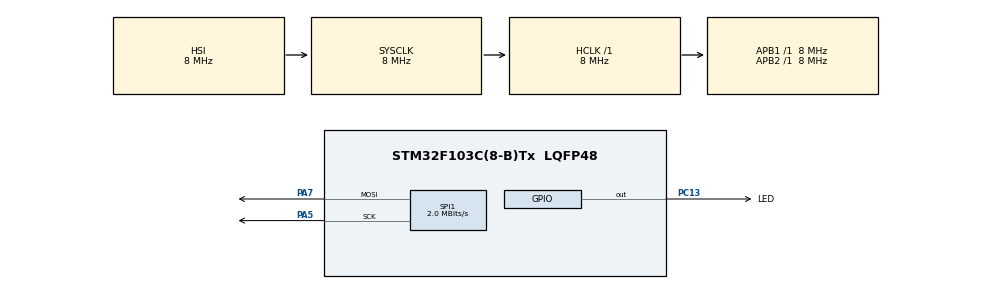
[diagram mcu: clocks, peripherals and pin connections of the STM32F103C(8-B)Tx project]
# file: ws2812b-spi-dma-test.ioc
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Mcu.Family=STM32F1
Dma.SPI1_TX.0.MemInc=DMA_MINC_ENABLE
Dma.SPI1_TX.0.PeriphInc=DMA_PINC_DISABLE
PA7.Mode=TX_Only_Simplex_Unidirect_Master
SPI1.VirtualType=VM_MASTER
PC13-TAMPER-RTC.Signal=GPIO_Output
SPI1.CLKPhase=SPI_PHASE_2EDGE
ProjectManager.StackSize=0x400
NVIC.DMA1_Channel3_IRQn=true\:0\:0\:false\:false\:true\:false\:true
PA13.Signal=SYS_JTMS-SWDIO
ProjectManager.TargetToolchain=Makefile
SPI1.Direction=SPI_DIRECTION_2LINES
Dma.SPI1_TX.0.PeriphDataAlignment=DMA_PDATAALIGN_BYTE
RCC.HCLKFreq_Value=8000000
Dma.SPI1_TX.0.Direction=DMA_MEMORY_TO_PERIPH
RCC.APB2TimFreq_Value=8000000
SPI1.CalculateBaudRate=2.0 MBits/s
RCC.USBFreq_Value=8000000
RCC.AHBFreq_Value=8000000
PA5.Signal=SPI1_SCK
board=custom
PC13-TAMPER-RTC.GPIO_Label=LED
RCC.APB2Freq_Value=8000000
SPI1.Mode=SPI_MODE_MASTER
PA14.Mode=Serial_Wire
Dma.SPI1_TX.0.Instance=DMA1_Channel3
PA13.Mode=Serial_Wire
Mcu.Name=STM32F103C(8-B)Tx
Dma.SPI1_TX.0.Mode=DMA_NORMAL
RCC.SYSCLKFreq_VALUE=8000000
Mcu.Package=LQFP48
PA14.Signal=SYS_JTCK-SWCLK
ProjectManager.HeapSize=0x200
Dma.SPI1_TX.0.Priority=DMA_PRIORITY_LOW
Dma.SPI1_TX.0.MemDataAlignment=DMA_MDATAALIGN_BYTE
NVIC.PriorityGroup=NVIC_PRIORITYGROUP_4
RCC.APB1TimFreq_Value=8000000
Dma.Request0=SPI1_TX
RCC.APB1Freq_Value=8000000
SPI1.BaudRatePrescaler=SPI_BAUDRATEPRESCALER_4
PA5.Mode=TX_Only_Simplex_Unidirect_Master
PA7.Signal=SPI1_MOSI

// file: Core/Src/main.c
/* USER CODE BEGIN Header */
/**
  ******************************************************************************
  * @file           : main.c
  * @brief          : Main program body
  ******************************************************************************
  * @attention
  *
  * <h2><center>&copy; Copyright (c) 2021 STMicroelectronics.
  * All rights reserved.</center></h2>
  *
  * This software component is licensed by ST under BSD 3-Clause license,
  * the "License"; You may not use this file except in compliance with the
  * License. You may obtain a copy of the License at:
  *                        opensource.org/licenses/BSD-3-Clause
  *
  ******************************************************************************
  */
/* USER CODE END Header */
#include "main.h"

/* USER CODE BEGIN Includes */
#include <string.h>
#include <stdlib.h>
#include <math.h>
#include <alloca.h>
/* USER CODE END Includes */

/* USER CODE BEGIN PD */
#define SPI_BITS_PER_BIT 3
#define NUM_RESET_BYTES 100
/* USER CODE END PD */

SPI_HandleTypeDef hspi1;
DMA_HandleTypeDef hdma_spi1_tx;

void SystemClock_Config(void);
static void MX_GPIO_Init(void);
static void MX_DMA_Init(void);
static void MX_SPI1_Init(void);
/* USER CODE BEGIN PFP */
void hsv_to_rgb(double h, double s, double l, uint8_t *r, uint8_t *g, uint8_t *b);
/* USER CODE END PFP */

/* USER CODE BEGIN 0 */

uint8_t *write_byte(uint8_t byte, uint8_t *buffer) {
  int expanded = 0;
  for (int i=7; i>=0; i--) {
    expanded <<= 3;

    if (byte & (1 << i)) {
      expanded |= 0b110;
    }
    else {
      expanded |= 0b100;
    }
  }

  *buffer = expanded >> 16;
  *(buffer + 1) = (expanded >> 8) & 0xFF;
  *(buffer + 2) = expanded & 0xFF;
  return buffer + 3;
}

// returns the size of memory required by the framebuffer. the framebuffer
// expects you to allocate at least this amount of memory, and then call
// new_framebuffer with it.
size_t get_framebuffer_size(size_t num_leds) {
  size_t spi_buffer_size = num_leds * 3 * SPI_BITS_PER_BIT + NUM_RESET_BYTES;
  return spi_buffer_size;
}

// make a new framebuffer. backing_memory must be a pointer to a usable
// region of memory at least get_framebuffer_size(num_leds) bytes big.
FrameBuffer new_framebuffer(size_t num_leds, void *backing_memory) {

  // initialize reset bytes
  size_t spi_buffer_size = get_framebuffer_size(num_leds);
  memset(backing_memory + spi_buffer_size - NUM_RESET_BYTES, 0, NUM_RESET_BYTES);

  FrameBuffer fb = {
    .spi_buffer = (uint8_t *) backing_memory,
    .spi_buffer_size = spi_buffer_size,
    .write_ptr = (uint8_t *) backing_memory,
    .num_leds = num_leds,
  };

  return fb;
}

// resets the position of the write index, allowing you to
// fill the framebuffer with new values
void clear_framebuffer(FrameBuffer *fb) {
  fb->write_ptr = fb->spi_buffer;
}

// sets the color of the next led in the chain, up to fb.num_leds.
// returns -1 if all leds have been set already, 0 otherwise.
int framebuffer_push_rgb(FrameBuffer *fb, uint8_t red, uint8_t green, uint8_t blue) {

  // // reserve 100 bytes for resetting
  // reserve 100 bytes for resetting
  size_t writable_spi_buffer_size = fb->spi_buffer_size - NUM_RESET_BYTES;
  if (fb->write_ptr >= (fb->spi_buffer + writable_spi_buffer_size)) {
    return -1;
  }

  fb->write_ptr = write_byte(green, fb->write_ptr);
  fb->write_ptr = write_byte(red, fb->write_ptr);
  fb->write_ptr = write_byte(blue, fb->write_ptr);

  return 0;
}

int framebuffer_push_hsv(FrameBuffer *fb, uint8_t h, uint8_t s, uint8_t v) {
    /**
     * Convert an HSV color value to RGB. Conversion formula
     * adapted from http://en.wikipedia.org/wiki/HSV_color_space.
     * Assumes h, s, and v are contained in the set [0, 1] and
     * returns r, g, and b in the set [0, 255].
     *
     * based on: https://axonflux.com/handy-rgb-to-hsl-and-rgb-to-hsv-color-model-c
     */

    uint16_t h6 = h * 6;
    uint8_t i = h6 >> 8; // integer part
    uint8_t f = h6 & 0xFF; // fractional part

    uint8_t p = v * (256 - s) >> 8;
    uint8_t q = v * (256 - ((f * s) >> 8)) >> 8;
    uint8_t t = v * (256 - (((256 - f) * s) >> 8)) >> 8;

    double select[] = {v, q, p, p, t, v};
    uint8_t r = select[(int) i % 6];
    uint8_t g = select[((int) i + 2) % 6];
    uint8_t b = select[((int) i + 4) % 6];

    return framebuffer_push_rgb(fb, r, g, b);
}

/* USER CODE END 0 */

int main(void)
{

  /* MCU Configuration--------------------------------------------------------*/

  /* Reset of all peripherals, Initializes the Flash interface and the Systick. */
  HAL_Init();

  /* Configure the system clock */
  SystemClock_Config();

  /* Initialize all configured peripherals */
  MX_GPIO_Init();
  MX_DMA_Init();
  MX_SPI1_Init();
  /* USER CODE BEGIN 2 */

  size_t num_leds = 100;
  size_t backing_buffer_size = get_framebuffer_size(num_leds);
  void *backing_buffer = alloca(backing_buffer_size);
  FrameBuffer framebuffer = new_framebuffer(num_leds, backing_buffer);

  void *renderer_data = init_renderer();

  /* USER CODE END 2 */

  /* Infinite loop */
  /* USER CODE BEGIN WHILE */
  render_frame(renderer_data, &framebuffer, HAL_GetTick());
  while (1)
  {

    if (HAL_SPI_Transmit_DMA(&hspi1, framebuffer.spi_buffer, framebuffer.spi_buffer_size) != HAL_OK) {
      Error_Handler();
    }

    render_frame(renderer_data, &framebuffer, HAL_GetTick());

    while (HAL_SPI_GetState(&hspi1) != HAL_SPI_STATE_READY) {
    }

    /* USER CODE END WHILE */

  }
}

void SystemClock_Config(void)
{
  RCC_OscInitTypeDef RCC_OscInitStruct = {0};
  RCC_ClkInitTypeDef RCC_ClkInitStruct = {0};

  /** Initializes the RCC Oscillators according to the specified parameters
  * in the RCC_OscInitTypeDef structure.
  */
  RCC_OscInitStruct.OscillatorType = RCC_OSCILLATORTYPE_HSI;
  RCC_OscInitStruct.HSIState = RCC_HSI_ON;
  RCC_OscInitStruct.HSICalibrationValue = RCC_HSICALIBRATION_DEFAULT;
  RCC_OscInitStruct.PLL.PLLState = RCC_PLL_NONE;
  if (HAL_RCC_OscConfig(&RCC_OscInitStruct) != HAL_OK)
  {
    Error_Handler();
  }
  /** Initializes the CPU, AHB and APB buses clocks
  */
  RCC_ClkInitStruct.ClockType = RCC_CLOCKTYPE_HCLK|RCC_CLOCKTYPE_SYSCLK
                              |RCC_CLOCKTYPE_PCLK1|RCC_CLOCKTYPE_PCLK2;
  RCC_ClkInitStruct.SYSCLKSource = RCC_SYSCLKSOURCE_HSI;
  RCC_ClkInitStruct.AHBCLKDivider = RCC_SYSCLK_DIV1;
  RCC_ClkInitStruct.APB1CLKDivider = RCC_HCLK_DIV1;
  RCC_ClkInitStruct.APB2CLKDivider = RCC_HCLK_DIV1;

  if (HAL_RCC_ClockConfig(&RCC_ClkInitStruct, FLASH_LATENCY_0) != HAL_OK)
  {
    Error_Handler();
  }
}

static void MX_SPI1_Init(void)
{

  /* SPI1 parameter configuration*/
  hspi1.Instance = SPI1;
  hspi1.Init.Mode = SPI_MODE_MASTER;
  hspi1.Init.Direction = SPI_DIRECTION_2LINES;
  hspi1.Init.DataSize = SPI_DATASIZE_8BIT;
  hspi1.Init.CLKPolarity = SPI_POLARITY_LOW;
  hspi1.Init.CLKPhase = SPI_PHASE_2EDGE;
  hspi1.Init.NSS = SPI_NSS_SOFT;
  hspi1.Init.BaudRatePrescaler = SPI_BAUDRATEPRESCALER_4;
  hspi1.Init.FirstBit = SPI_FIRSTBIT_MSB;
  hspi1.Init.TIMode = SPI_TIMODE_DISABLE;
  hspi1.Init.CRCCalculation = SPI_CRCCALCULATION_DISABLE;
  hspi1.Init.CRCPolynomial = 10;
  if (HAL_SPI_Init(&hspi1) != HAL_OK)
  {
    Error_Handler();
  }

}

static void MX_DMA_Init(void)
{

  /* DMA controller clock enable */
  __HAL_RCC_DMA1_CLK_ENABLE();

  /* DMA interrupt init */
  /* DMA1_Channel3_IRQn interrupt configuration */
  HAL_NVIC_SetPriority(DMA1_Channel3_IRQn, 0, 0);
  HAL_NVIC_EnableIRQ(DMA1_Channel3_IRQn);

}

static void MX_GPIO_Init(void)
{

  /* GPIO Ports Clock Enable */
  __HAL_RCC_GPIOA_CLK_ENABLE();

}

void Error_Handler(void)
{
  __disable_irq();
  while (1)
  {
  }
}

/************************ (C) COPYRIGHT STMicroelectronics *****END OF FILE****/
